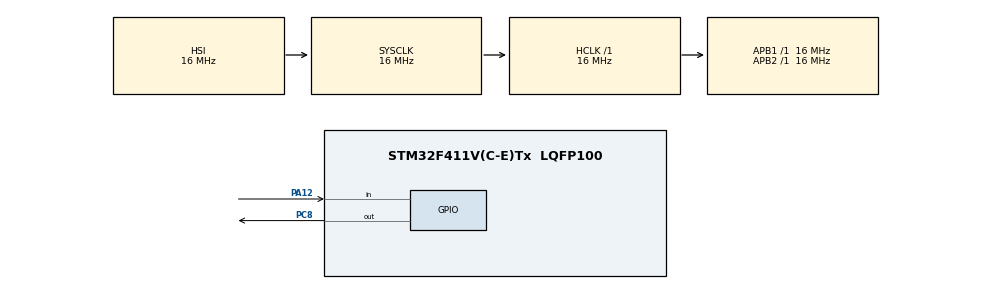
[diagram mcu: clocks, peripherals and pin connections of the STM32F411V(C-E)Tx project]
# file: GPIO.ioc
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Mcu.Family=STM32F4
Mcu.Name=STM32F411V(C-E)Tx
Mcu.Package=LQFP100
NVIC.PriorityGroup=NVIC_PRIORITYGROUP_4
PA12.GPIO_PuPd=GPIO_PULLUP
PA12.Signal=GPIO_Input
PC8.Signal=GPIO_Output
PH0\ -\ OSC_IN.Mode=HSE-External-Oscillator
PH0\ -\ OSC_IN.Signal=RCC_OSC_IN
PH1\ -\ OSC_OUT.Mode=HSE-External-Oscillator
PH1\ -\ OSC_OUT.Signal=RCC_OSC_OUT
ProjectManager.HeapSize=0x200
ProjectManager.StackSize=0x400
ProjectManager.TargetToolchain=STM32CubeIDE
RCC.AHBFreq_Value=16000000
RCC.APB1Freq_Value=16000000
RCC.APB2Freq_Value=16000000
RCC.CortexFreq_Value=16000000
RCC.HSE_VALUE=25000000
RCC.HSI_VALUE=16000000
RCC.LSE_VALUE=32768
RCC.SYSCLKFreq_VALUE=16000000
RCC.VCOOutputFreq_Value=192000000
board=custom

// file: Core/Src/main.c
/* USER CODE BEGIN Header */
/**
  ******************************************************************************
  * @file           : main.c
  * @brief          : Main program body
  ******************************************************************************
  * @attention
  *
  * Copyright (c) 2024 STMicroelectronics.
  * All rights reserved.
  *
  * This software is licensed under terms that can be found in the LICENSE file
  * in the root directory of this software component.
  * If no LICENSE file comes with this software, it is provided AS-IS.
  *
  ******************************************************************************
  */
/* USER CODE END Header */
#include "main.h"

/* USER CODE BEGIN PD */
#define nutnhan GPIOA->IDR>>12&0x1
/* USER CODE END PD */

void SystemClock_Config(void);
static void MX_GPIO_Init(void);

/* USER CODE BEGIN 0 */
void led_init(void){

	 _HAL_RCC_GPIOC_CLK_ENABLE();
	 GPIOD->MODER&=~(15U<<16)
	 GPIOD->MODER|=(1U<<16)||(1U<<18); // 01: General purpose output mode PIN 8  || 9
     GPIOD->OTYPER&=~(3U<<8);
     GPIOD->OTYPER|=(3U<<8);  //pp1 pin 8 9
}
void button_init(void){
	 _HAL_RCC_GPIOA_CLK_ENABLE();
	 GPIOA->MODER &=~(3U<<24);  // input state
     GPIOA->PUPDR&=~(3U<<24);
     GPIOA->PUPDR|=(1U<<24); // PULL UP
}
enum {
	LED_ON =1,
	LED_OFF=0,

}led_state;
void SANGLED(int number,int state){
	if(state=LED_ON){
		GPIOD->ODR|=(1<<number);		}
	else {
		GPIOD->ODR&=~(1<<number);
	}
}

/* USER CODE END 0 */

int main(void)
{

  /* MCU Configuration--------------------------------------------------------*/

  /* Reset of all peripherals, Initializes the Flash interface and the Systick. */
  HAL_Init();

  /* Configure the system clock */
  SystemClock_Config();

  /* Initialize all configured peripherals */
  MX_GPIO_Init();

  /* Infinite loop */
  /* USER CODE BEGIN WHILE */
  while (1)
  {
	  if(!(nutnhan)){
		  sangled(8,1);
		  HAL_DELAY(200);
	  }
	  else{

		 sangled(8,0);
		  HAL_DELAY(200);
	  }

    /* USER CODE END WHILE */

  }
}

void SystemClock_Config(void)
{
  RCC_OscInitTypeDef RCC_OscInitStruct = {0};
  RCC_ClkInitTypeDef RCC_ClkInitStruct = {0};

  /** Configure the main internal regulator output voltage
  */
  __HAL_RCC_PWR_CLK_ENABLE();
  __HAL_PWR_VOLTAGESCALING_CONFIG(PWR_REGULATOR_VOLTAGE_SCALE1);

  /** Initializes the RCC Oscillators according to the specified parameters
  * in the RCC_OscInitTypeDef structure.
  */
  RCC_OscInitStruct.OscillatorType = RCC_OSCILLATORTYPE_HSI;
  RCC_OscInitStruct.HSIState = RCC_HSI_ON;
  RCC_OscInitStruct.HSICalibrationValue = RCC_HSICALIBRATION_DEFAULT;
  RCC_OscInitStruct.PLL.PLLState = RCC_PLL_NONE;
  if (HAL_RCC_OscConfig(&RCC_OscInitStruct) != HAL_OK)
  {
    Error_Handler();
  }

  /** Initializes the CPU, AHB and APB buses clocks
  */
  RCC_ClkInitStruct.ClockType = RCC_CLOCKTYPE_HCLK|RCC_CLOCKTYPE_SYSCLK
                              |RCC_CLOCKTYPE_PCLK1|RCC_CLOCKTYPE_PCLK2;
  RCC_ClkInitStruct.SYSCLKSource = RCC_SYSCLKSOURCE_HSI;
  RCC_ClkInitStruct.AHBCLKDivider = RCC_SYSCLK_DIV1;
  RCC_ClkInitStruct.APB1CLKDivider = RCC_HCLK_DIV1;
  RCC_ClkInitStruct.APB2CLKDivider = RCC_HCLK_DIV1;

  if (HAL_RCC_ClockConfig(&RCC_ClkInitStruct, FLASH_LATENCY_0) != HAL_OK)
  {
    Error_Handler();
  }
}

static void MX_GPIO_Init(void)
{
  GPIO_InitTypeDef GPIO_InitStruct = {0};

  /* GPIO Ports Clock Enable */
  __HAL_RCC_GPIOH_CLK_ENABLE();
  __HAL_RCC_GPIOC_CLK_ENABLE();
  __HAL_RCC_GPIOA_CLK_ENABLE();

  /*Configure GPIO pin Output Level */
  HAL_GPIO_WritePin(GPIOC, GPIO_PIN_8, GPIO_PIN_RESET);

  /*Configure GPIO pin : PC8 */
  GPIO_InitStruct.Pin = GPIO_PIN_8;
  GPIO_InitStruct.Mode = GPIO_MODE_OUTPUT_PP;
  GPIO_InitStruct.Pull = GPIO_NOPULL;
  GPIO_InitStruct.Speed = GPIO_SPEED_FREQ_LOW;
  HAL_GPIO_Init(GPIOC, &GPIO_InitStruct);

  /*Configure GPIO pin : PA12 */
  GPIO_InitStruct.Pin = GPIO_PIN_12;
  GPIO_InitStruct.Mode = GPIO_MODE_INPUT;
  GPIO_InitStruct.Pull = GPIO_PULLUP;
  HAL_GPIO_Init(GPIOA, &GPIO_InitStruct);

}

void Error_Handler(void)
{
  __disable_irq();
  while (1)
  {
  }
}
